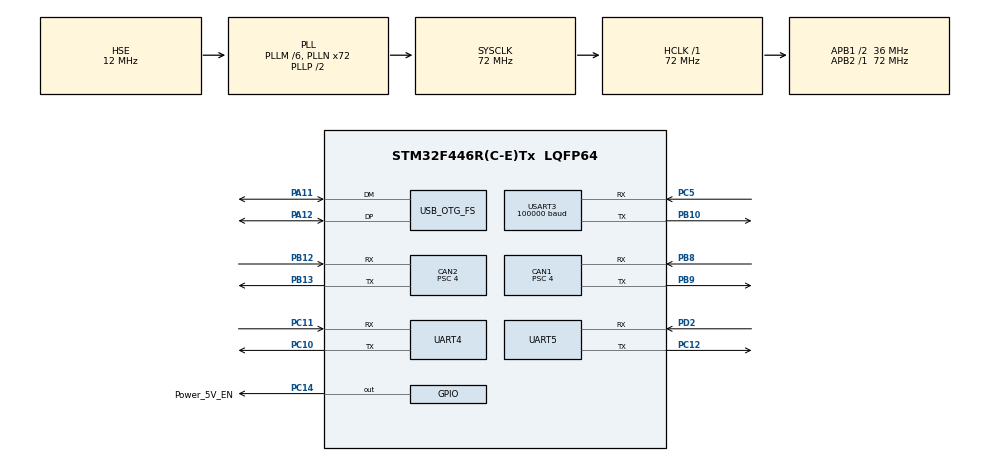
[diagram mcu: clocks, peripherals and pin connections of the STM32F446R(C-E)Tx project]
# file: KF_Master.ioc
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CAN1.BS1=CAN_BS1_6TQ
CAN1.BS2=CAN_BS2_2TQ
CAN1.CalculateBaudRate=1000000
CAN1.CalculateTimeBit=1000
CAN1.CalculateTimeQuantum=111.11111111111111
CAN1.Prescaler=4
CAN2.BS1=CAN_BS1_6TQ
CAN2.BS2=CAN_BS2_2TQ
CAN2.CalculateBaudRate=1000000
CAN2.CalculateTimeBit=1000
CAN2.CalculateTimeQuantum=111.11111111111111
CAN2.Prescaler=4
FREERTOS.Events01=KFQEvent,Dynamic,NULL
FREERTOS.Tasks01=InitTask,24,256,StartInitTask,Default,NULL,Dynamic,NULL,NULL;CmdTask,24,256,StartCmdTask,As external,NULL,Dynamic,NULL,NULL
Mcu.Family=STM32F4
Mcu.Name=STM32F446R(C-E)Tx
Mcu.Package=LQFP64
NVIC.CAN1_RX0_IRQn=true\:5\:0\:false\:false\:true\:true\:true\:true\:true
NVIC.CAN1_RX1_IRQn=true\:5\:0\:false\:false\:true\:true\:true\:true\:true
NVIC.CAN2_RX0_IRQn=true\:5\:0\:false\:false\:true\:true\:true\:true\:true
NVIC.CAN2_RX1_IRQn=true\:5\:0\:false\:false\:true\:true\:true\:true\:true
NVIC.OTG_FS_IRQn=true\:5\:0\:false\:false\:true\:true\:false\:true\:true
NVIC.PriorityGroup=NVIC_PRIORITYGROUP_4
NVIC.UART4_IRQn=true\:5\:0\:false\:false\:true\:true\:true\:true\:true
NVIC.UART5_IRQn=true\:5\:0\:false\:false\:true\:true\:true\:true\:true
NVIC.USART3_IRQn=true\:5\:0\:false\:false\:true\:true\:true\:true\:true
PA11.Mode=Device_Only
PA11.Signal=USB_OTG_FS_DM
PA12.Mode=Device_Only
PA12.Signal=USB_OTG_FS_DP
PB10.Mode=Asynchronous
PB10.Signal=USART3_TX
PB12.Mode=CAN_Activate
PB12.Signal=CAN2_RX
PB13.Mode=CAN_Activate
PB13.Signal=CAN2_TX
PB8.Mode=CAN_Activate
PB8.Signal=CAN1_RX
PB9.Mode=CAN_Activate
PB9.Signal=CAN1_TX
PC10.Mode=Asynchronous
PC10.Signal=UART4_TX
PC11.Mode=Asynchronous
PC11.Signal=UART4_RX
PC12.Mode=Asynchronous
PC12.Signal=UART5_TX
PC14-OSC32_IN.GPIO_Label=Power_5V_EN
PC14-OSC32_IN.PinState=GPIO_PIN_SET
PC14-OSC32_IN.Signal=GPIO_Output
PC5.Mode=Asynchronous
PC5.Signal=USART3_RX
PD2.Mode=Asynchronous
PD2.Signal=UART5_RX
PH0-OSC_IN.Mode=HSE-External-Oscillator
PH0-OSC_IN.Signal=RCC_OSC_IN
PH1-OSC_OUT.Mode=HSE-External-Oscillator
PH1-OSC_OUT.Signal=RCC_OSC_OUT
ProjectManager.HeapSize=0x200
ProjectManager.StackSize=0x400
ProjectManager.TargetToolchain=STM32CubeIDE
RCC.AHBFreq_Value=72000000
RCC.APB1CLKDivider=RCC_HCLK_DIV2
RCC.APB1Freq_Value=36000000
RCC.APB1TimFreq_Value=72000000
RCC.APB2Freq_Value=72000000
RCC.APB2TimFreq_Value=72000000
RCC.CortexFreq_Value=72000000
RCC.HCLKFreq_Value=72000000
RCC.HSE_VALUE=12000000
RCC.PLLM=6
RCC.PLLN=72
RCC.PLLQ=3
RCC.PLLSourceVirtual=RCC_PLLSOURCE_HSE
RCC.SYSCLKFreq_VALUE=72000000
RCC.SYSCLKSource=RCC_SYSCLKSOURCE_PLLCLK
RCC.USBFreq_Value=48000000
RCC.VCOOutputFreq_Value=144000000
UART4.VirtualMode=Asynchronous
UART5.VirtualMode=Asynchronous
USART3.BaudRate=100000
USART3.Parity=PARITY_EVEN
USART3.StopBits=STOPBITS_1
USART3.VirtualMode=VM_ASYNC
USART3.WordLength=WORDLENGTH_9B
USB_DEVICE.CLASS_NAME_FS=CDC
USB_DEVICE.VirtualMode-CDC_FS=Cdc
USB_DEVICE.VirtualModeFS=Cdc_FS
USB_OTG_FS.VirtualMode=Device_Only
VP_FREERTOS_VS_CMSIS_V2.Mode=CMSIS_V2
VP_USB_DEVICE_VS_USB_DEVICE_CDC_FS.Mode=CDC_FS
board=custom

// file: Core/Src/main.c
/* USER CODE BEGIN Header */
/**
  ******************************************************************************
  * @file           : main.c
  * @brief          : Main program body
  ******************************************************************************
  * @attention
  *
  * Copyright (c) 2026 STMicroelectronics.
  * All rights reserved.
  *
  * This software is licensed under terms that can be found in the LICENSE file
  * in the root directory of this software component.
  * If no LICENSE file comes with this software, it is provided AS-IS.
  *
  ******************************************************************************
  */
/* USER CODE END Header */
#include "main.h"
#include "cmsis_os.h"
#include "can.h"
#include "usart.h"
#include "usb_device.h"
#include "gpio.h"

void SystemClock_Config(void);
void MX_FREERTOS_Init(void);

int main(void)
{

  /* MCU Configuration--------------------------------------------------------*/

  /* Reset of all peripherals, Initializes the Flash interface and the Systick. */
  HAL_Init();

  /* Configure the system clock */
  SystemClock_Config();

  /* Initialize all configured peripherals */
  MX_GPIO_Init();
  MX_CAN1_Init();
  MX_USART3_UART_Init();
  MX_UART5_Init();
  MX_UART4_Init();
  MX_CAN2_Init();

  /* Init scheduler */
  osKernelInitialize();  /* Call init function for freertos objects (in cmsis_os2.c) */
  MX_FREERTOS_Init();

  /* Start scheduler */
  osKernelStart();

  /* We should never get here as control is now taken by the scheduler */

  /* Infinite loop */
  while (1)
  {

  }
}

void SystemClock_Config(void)
{
  RCC_OscInitTypeDef RCC_OscInitStruct = {0};
  RCC_ClkInitTypeDef RCC_ClkInitStruct = {0};

  /** Configure the main internal regulator output voltage
  */
  __HAL_RCC_PWR_CLK_ENABLE();
  __HAL_PWR_VOLTAGESCALING_CONFIG(PWR_REGULATOR_VOLTAGE_SCALE3);

  /** Initializes the RCC Oscillators according to the specified parameters
  * in the RCC_OscInitTypeDef structure.
  */
  RCC_OscInitStruct.OscillatorType = RCC_OSCILLATORTYPE_HSE;
  RCC_OscInitStruct.HSEState = RCC_HSE_ON;
  RCC_OscInitStruct.PLL.PLLState = RCC_PLL_ON;
  RCC_OscInitStruct.PLL.PLLSource = RCC_PLLSOURCE_HSE;
  RCC_OscInitStruct.PLL.PLLM = 6;
  RCC_OscInitStruct.PLL.PLLN = 72;
  RCC_OscInitStruct.PLL.PLLP = RCC_PLLP_DIV2;
  RCC_OscInitStruct.PLL.PLLQ = 3;
  RCC_OscInitStruct.PLL.PLLR = 2;
  if (HAL_RCC_OscConfig(&RCC_OscInitStruct) != HAL_OK)
  {
    Error_Handler();
  }

  /** Initializes the CPU, AHB and APB buses clocks
  */
  RCC_ClkInitStruct.ClockType = RCC_CLOCKTYPE_HCLK|RCC_CLOCKTYPE_SYSCLK
                              |RCC_CLOCKTYPE_PCLK1|RCC_CLOCKTYPE_PCLK2;
  RCC_ClkInitStruct.SYSCLKSource = RCC_SYSCLKSOURCE_PLLCLK;
  RCC_ClkInitStruct.AHBCLKDivider = RCC_SYSCLK_DIV1;
  RCC_ClkInitStruct.APB1CLKDivider = RCC_HCLK_DIV2;
  RCC_ClkInitStruct.APB2CLKDivider = RCC_HCLK_DIV1;

  if (HAL_RCC_ClockConfig(&RCC_ClkInitStruct, FLASH_LATENCY_2) != HAL_OK)
  {
    Error_Handler();
  }
}

void Error_Handler(void)
{
  __disable_irq();
  while (1)
  {
  }
}

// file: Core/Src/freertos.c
/* USER CODE BEGIN Header */
/**
  ******************************************************************************
  * File Name          : freertos.c
  * Description        : Code for freertos applications
  ******************************************************************************
  * @attention
  *
  * Copyright (c) 2026 STMicroelectronics.
  * All rights reserved.
  *
  * This software is licensed under terms that can be found in the LICENSE file
  * in the root directory of this software component.
  * If no LICENSE file comes with this software, it is provided AS-IS.
  *
  ******************************************************************************
  */
/* USER CODE END Header */

#include "FreeRTOS.h"
#include "task.h"
#include "main.h"
#include "cmsis_os.h"

/* Definitions for InitTask */
osThreadId_t InitTaskHandle;
const osThreadAttr_t InitTask_attributes = {
  .name = "InitTask",
  .stack_size = 256 * 4,
  .priority = (osPriority_t) osPriorityNormal,
};
/* Definitions for CmdTask */
osThreadId_t CmdTaskHandle;
const osThreadAttr_t CmdTask_attributes = {
  .name = "CmdTask",
  .stack_size = 256 * 4,
  .priority = (osPriority_t) osPriorityNormal,
};
/* Definitions for KFQEvent */
osEventFlagsId_t KFQEventHandle;
const osEventFlagsAttr_t KFQEvent_attributes = {
  .name = "KFQEvent"
};

void StartInitTask(void *argument);
extern void StartCmdTask(void *argument);

extern void MX_USB_DEVICE_Init(void);
void MX_FREERTOS_Init(void); /* (MISRA C 2004 rule 8.1) */

void MX_FREERTOS_Init(void) {

  /* Create the thread(s) */
  /* creation of InitTask */
  InitTaskHandle = osThreadNew(StartInitTask, NULL, &InitTask_attributes);

  /* creation of CmdTask */
  CmdTaskHandle = osThreadNew(StartCmdTask, NULL, &CmdTask_attributes);

  /* Create the event(s) */
  /* creation of KFQEvent */
  KFQEventHandle = osEventFlagsNew(&KFQEvent_attributes);

}

void StartInitTask(void *argument)
{
  /* init code for USB_DEVICE */
  MX_USB_DEVICE_Init();
  /* USER CODE BEGIN StartInitTask */
  user_init();

  osThreadTerminate(InitTaskHandle);
  /* Infinite loop */
  for(;;)
  {
    osDelay(1);
  }
  /* USER CODE END StartInitTask */
}
